# CY8C5888LTI_LP097 register map
File version: 0.1
Registers are 8-bit, read-write, no defined reset value unless marked. A register's access mark holds for its fields unless they carry their own. Offsets are from the block's base; [hi:lo] are bit positions; 'fields as' and 'values as' point back to an identical list.

## I2C_DISPLAY
Base 0x00000000
0x4000640B I2C_DISPLAY_DATA — I2C Data Register
  [7:0] data — Read received data or write data to transmit.
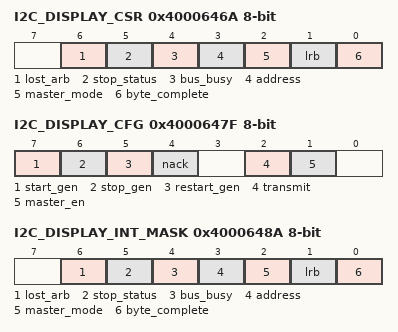
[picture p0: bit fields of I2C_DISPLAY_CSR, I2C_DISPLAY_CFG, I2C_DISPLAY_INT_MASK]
0x4000646A I2C_DISPLAY_CSR — I2C Status Register
  [6] lost_arb ro — If set, indicates arbitration was lost (multi-master and multi-master-slave modes).
  [5] stop_status ro — If set, indicates a Stop condition was detected on the bus.
  [4] bus_busy ro — If set, indicates the bus is busy. Data is currently being transmitted or received.
  [3] address ro — Address detection. If set, indicates that an address byte was sent.
  [2] master_mode ro — Indicates that a valid Start condition was generated and a hardware device is operating as bus master.
  [1] lrb ro — Last Received Bit. Indicates the state of the last received bit, which is the ACK/NAK received for the last byte transmitted. Cleared = ACK and set = NAK.
  [0] byte_complete ro — Transmit or receive status since the last read of this register. In Transmit mode this bit indicates that eight bits of data plus ACK/NAK have been transmitted since the last read. In Receive mode this bit indicates that eight bits of data have been received since the last read of this register.
0x4000647F I2C_DISPLAY_CFG — I2C Configuration Register
  [7] start_gen — Set to 1 to generate a Start condition on the bus. This bit must be cleared by firmware before initiating the next transaction.
  [6] stop_gen — Set to 1 to generate a Stop condition on the bus. This bit must be cleared by firmware before initiating the next transaction.
  [5] restart_gen — Set to 1 to generate a Restart condition on the bus. This bit must be cleared by firmware after a Restart condition is generated.
  [4] nack — Set to 1 to NAK the next read byte. Clear to ACK next read byte. This bit must be cleared by firmware between bytes.
  [2] transmit — Set to 1 to set the current mode to transmit or clear to 0 to receive a byte of data. This bit must be cleared by firmware before starting the next transmit or receive transaction.
  [1] master_en — Set to 1 to enable the master functionality.
0x4000648A I2C_DISPLAY_INT_MASK — I2C Interrupt Enable Mask
  [6] lost_arb — Enables interrupt from the corresponding bit in status register.
  [5] stop_status — Enables interrupt from the corresponding bit in status register.
  [4] bus_busy — Enables interrupt from the corresponding bit in status register.
  [3] address — Enables interrupt from the corresponding bit in status register.
  [2] master_mode — Enables interrupt from the corresponding bit in status register.
  [1] lrb — Enables interrupt from the corresponding bit in status register.
  [0] byte_complete — Enables interrupt from the corresponding bit in status register.

## UART_RX — UART
Base 0x00000000
0x40006425 RX_UART_RX_RX_ADDRESS1 — RX Address1 Register
0x40006435 RX_UART_RX_RX_ADDRESS2 — RX Address2 Register
0x40006445 RX_UART_RX_RX_DATA — RX Data Register
0x40006449 TX_UART_RX_TX_DATA — TX Data Register
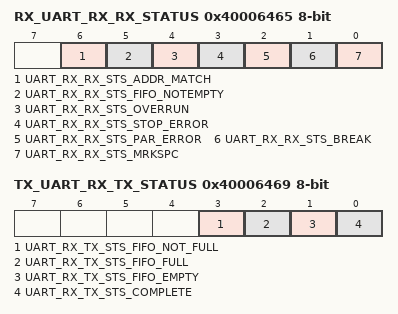
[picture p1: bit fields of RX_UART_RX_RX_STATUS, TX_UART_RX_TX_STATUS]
0x40006465 RX_UART_RX_RX_STATUS — RX status register
  [6] UART_RX_RX_STS_ADDR_MATCH ro, [5] UART_RX_RX_STS_FIFO_NOTEMPTY ro, [4] UART_RX_RX_STS_OVERRUN ro, [3] UART_RX_RX_STS_STOP_ERROR ro, [2] UART_RX_RX_STS_PAR_ERROR ro, [1] UART_RX_RX_STS_BREAK ro, [0] UART_RX_RX_STS_MRKSPC ro
0x40006469 TX_UART_RX_TX_STATUS — TX status register
  [3] UART_RX_TX_STS_FIFO_NOT_FULL ro, [2] UART_RX_TX_STS_FIFO_FULL ro, [1] UART_RX_TX_STS_FIFO_EMPTY ro, [0] UART_RX_TX_STS_COMPLETE ro

## UART_TX — UART
Base 0x00000000
0x40006424 RX_UART_TX_RX_ADDRESS1 — RX Address1 Register
0x40006434 RX_UART_TX_RX_ADDRESS2 — RX Address2 Register
0x40006443 TX_UART_TX_TX_DATA — TX Data Register
0x40006444 RX_UART_TX_RX_DATA — RX Data Register
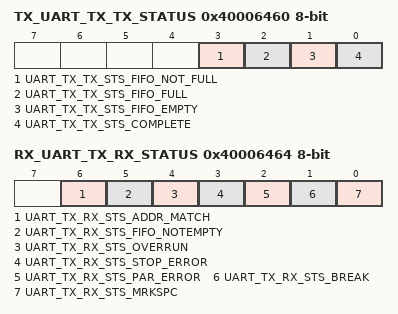
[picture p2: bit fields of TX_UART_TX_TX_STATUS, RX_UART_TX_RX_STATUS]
0x40006460 TX_UART_TX_TX_STATUS — TX status register
  [3] UART_TX_TX_STS_FIFO_NOT_FULL ro, [2] UART_TX_TX_STS_FIFO_FULL ro, [1] UART_TX_TX_STS_FIFO_EMPTY ro, [0] UART_TX_TX_STS_COMPLETE ro
0x40006464 RX_UART_TX_RX_STATUS — RX status register
  [6] UART_TX_RX_STS_ADDR_MATCH ro, [5] UART_TX_RX_STS_FIFO_NOTEMPTY ro, [4] UART_TX_RX_STS_OVERRUN ro, [3] UART_TX_RX_STS_STOP_ERROR ro, [2] UART_TX_RX_STS_PAR_ERROR ro, [1] UART_TX_RX_STS_BREAK ro, [0] UART_TX_RX_STS_MRKSPC ro

## BUZZER
Base 0x00000000
0x40006420 BUZZER_COMPARE_Reg 16-bit — UDB.D0 - Assigned Compare Value
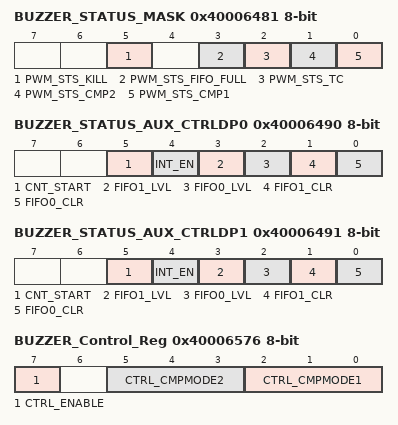
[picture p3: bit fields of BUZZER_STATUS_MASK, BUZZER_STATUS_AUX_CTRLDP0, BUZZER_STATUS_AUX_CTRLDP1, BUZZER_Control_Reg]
0x40006481 BUZZER_STATUS_MASK — UDB Status bits Interrupt Mask Enable Register
  [5] PWM_STS_KILL ro — Enables the Interrupt on Kill
  [3] PWM_STS_FIFO_FULL ro — FIFO Full Status Mask
  [2] PWM_STS_TC ro — Enables the Interrupt on Terminal Count
  [1] PWM_STS_CMP2 ro — Enables the Interrupt on Compare 2
  [0] PWM_STS_CMP1 ro — Enables the Interrupt on Compare 1
0x40006490 BUZZER_STATUS_AUX_CTRLDP0 — UDB Auxilliary Control Register
  [5] CNT_START — FIFO0 clear
    0=E_CNT_START0 (Disable counter); 1=E_CNT_START1 (Enable counter)
  [4] INT_EN
    0=E_INT_EN0 (Interrupt disabled); 1=E_INT_EN1 (Interrupt enabled)
  [3] FIFO1_LVL — FIFO level
    0=E_FIFO_LVL_0 (FIFO LVL: input mode: FIFO not full; output mode: FIFO not empty); 1=E_FIFO_LVL_1 (FIFO LVL: input mode: FIFO at least 1/2 empty; output mode: FIFO at least 1/2 full)
  [2] FIFO0_LVL — FIFO level
    values as FIFO1_LVL
  [1] FIFO1_CLR — FIFO1 clear
    0=E_FIFO_CLR_0 (Normal FIFO operation); 1=E_FIFO_CLR_1 (Clear FIFO state)
  [0] FIFO0_CLR — FIFO0 clear
    values as FIFO1_CLR
0x40006491 BUZZER_STATUS_AUX_CTRLDP1 — UDB Auxilliary Control Register
  fields as BUZZER_STATUS_AUX_CTRLDP0
0x40006576 BUZZER_Control_Reg — UDB Control Register - Assigned Control Register Value
  [7] CTRL_ENABLE — Enable the PWM
  [5:3] CTRL_CMPMODE2 — Compare mode 2
  [2:0] CTRL_CMPMODE1 — Compare mode 1

## PWM_MOTOR_SPEED
Base 0x00000000
0x4000642C PWM_MOTOR_SPEED_COMPARE_Reg 16-bit — UDB.D0 - Assigned Compare Value
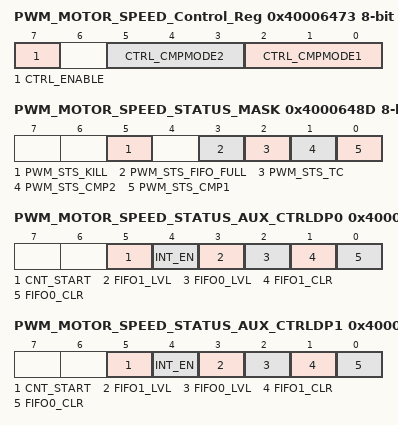
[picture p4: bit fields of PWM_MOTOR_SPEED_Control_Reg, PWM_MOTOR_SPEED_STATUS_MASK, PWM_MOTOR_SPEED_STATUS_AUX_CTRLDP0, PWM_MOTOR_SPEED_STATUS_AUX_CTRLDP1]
0x40006473 PWM_MOTOR_SPEED_Control_Reg — UDB Control Register - Assigned Control Register Value
  [7] CTRL_ENABLE — Enable the PWM
  [5:3] CTRL_CMPMODE2 — Compare mode 2
  [2:0] CTRL_CMPMODE1 — Compare mode 1
0x4000648D PWM_MOTOR_SPEED_STATUS_MASK — UDB Status bits Interrupt Mask Enable Register
  [5] PWM_STS_KILL ro — Enables the Interrupt on Kill
  [3] PWM_STS_FIFO_FULL ro — FIFO Full Status Mask
  [2] PWM_STS_TC ro — Enables the Interrupt on Terminal Count
  [1] PWM_STS_CMP2 ro — Enables the Interrupt on Compare 2
  [0] PWM_STS_CMP1 ro — Enables the Interrupt on Compare 1
0x4000649C PWM_MOTOR_SPEED_STATUS_AUX_CTRLDP0 — UDB Auxilliary Control Register
  [5] CNT_START — FIFO0 clear
    0=E_CNT_START0 (Disable counter); 1=E_CNT_START1 (Enable counter)
  [4] INT_EN
    0=E_INT_EN0 (Interrupt disabled); 1=E_INT_EN1 (Interrupt enabled)
  [3] FIFO1_LVL — FIFO level
    0=E_FIFO_LVL_0 (FIFO LVL: input mode: FIFO not full; output mode: FIFO not empty); 1=E_FIFO_LVL_1 (FIFO LVL: input mode: FIFO at least 1/2 empty; output mode: FIFO at least 1/2 full)
  [2] FIFO0_LVL — FIFO level
    values as FIFO1_LVL
  [1] FIFO1_CLR — FIFO1 clear
    0=E_FIFO_CLR_0 (Normal FIFO operation); 1=E_FIFO_CLR_1 (Clear FIFO state)
  [0] FIFO0_CLR — FIFO0 clear
    values as FIFO1_CLR
0x4000649D PWM_MOTOR_SPEED_STATUS_AUX_CTRLDP1 — UDB Auxilliary Control Register
  fields as PWM_MOTOR_SPEED_STATUS_AUX_CTRLDP0
